# M0A21 register map
File version: 1.0
Registers are 32-bit, read-write, reset 0x0 unless marked. A register's access mark holds for its fields unless they carry their own. Offsets are from the block's base; [hi:lo] are bit positions; {n}, {i} and the like mark numbered series; 'fields as' and 'values as' point back to an identical list.

## SYS — SYS Register Map
Base 0x40000000
0x00 SYS_PDID ro reset not defined — Part Device Identification Number Register
  [31:0] PDID — Part Device Identification Number (Read Only). This register reflects device part number code. Software can read this register to identify which device is used.
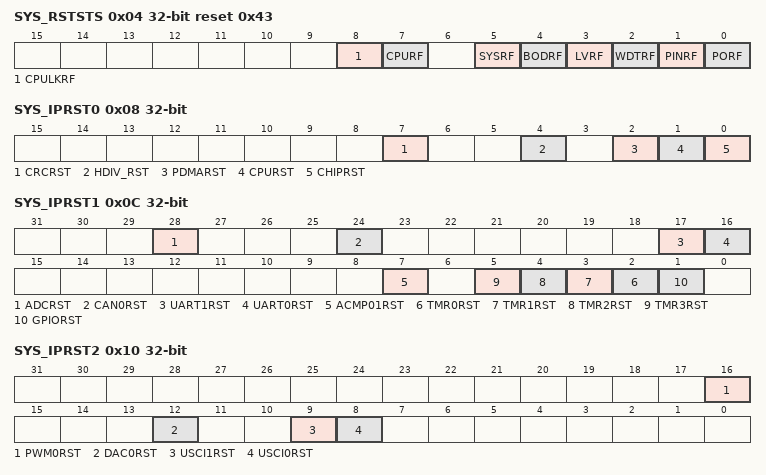
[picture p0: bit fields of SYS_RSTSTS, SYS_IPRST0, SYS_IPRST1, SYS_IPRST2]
0x04 SYS_RSTSTS reset 0x43 — System Reset Status Register
  [8] CPULKRF — CPU Lockup Reset Flag. Note: Write 1 to clear this bit to 0. Note 2: When CPU lockup happened under ICE is connected, This flag will set to 1 but chip will not reset.
    0=No reset from CPU lockup happened; 1=The Cortex-M0 lockup happened and chip is reset
  [7] CPURF — CPU Reset Flag. The CPU reset flag is set by hardware if software writes CPURST (SYS_IPRST0[1]) 1 to reset Cortex- M0 Core and Flash Memory Controller (FMC). Note: Write to clear this bit to 0.
    0=No reset from CPU; 1=The Cortex-M0 Core and FMC are reset by software setting CPURST to 1
  [5] SYSRF — System Reset Flag. The system reset flag is set by the 'Reset Signal' from the Cortex-M0 Core to indicate the previous reset source. Note: Write 1 to clear this bit to 0.
    0=No reset from Cortex-M0; 1=The Cortex- M0 had issued the reset signal to reset the system by writing 1 to the bit SYSRESETREQ(AIRCR[2], Application Interrupt and Reset Control Register, address = 0xE000ED0C) in system control registers of Cortex-M0 core
  [4] BODRF — BOD Reset Flag. The BOD reset flag is set by the 'Reset Signal' from the Brown-Out Detector to indicate the previous reset source. Note: Write 1 to clear this bit to 0.
    0=No reset from BOD; 1=The BOD had issued the reset signal to reset the system
  [3] LVRF — LVR Reset Flag. The LVR reset flag is set by the 'Reset Signal' from the Low Voltage Reset Controller to indicate the previous reset source. Note: Write 1 to clear this bit to 0.
    0=No reset from LVR; 1=LVR controller had issued the reset signal to reset the system
  [2] WDTRF — WDT Reset Flag. The WDT reset flag is set by the 'Reset Signal' from the Watchdog Timer or Window Watchdog Timer to indicate the previous reset source. Note 1: Write 1 to clear this bit to 0. Note 2: Watchdog Timer register RSTF(WDT_CTL[2]) bit is set if the system has been reset by WDT time-out reset. Window Watchdog Timer register WWDTRF(WWDT_STATUS[1]) bit is set if the system has been reset by WWDT time-out reset.
    0=No reset from watchdog timer or window watchdog timer; 1=The watchdog timer or window watchdog timer had issued the reset signal to reset the system
  [1] PINRF — NRESET Pin Reset Flag. The nRESET pin reset flag is set by the 'Reset Signal' from the nRESET Pin to indicate the previous reset source. Note: Write 1 to clear this bit to 0.
    0=No reset from nRESET pin; 1=Pin nRESET had issued the reset signal to reset the system
  [0] PORF — POR Reset Flag. The POR reset flag is set by the 'Reset Signal' from the Power-on Reset (POR) Controller or bit CHIPRST (SYS_IPRST0[0]) to indicate the previous reset source. Note: Write 1 to clear this bit to 0.
    0=No reset from POR or CHIPRST; 1=Power-on Reset (POR) or CHIPRST had issued the reset signal to reset the system
0x08 SYS_IPRST0 — Peripheral Reset Control Register 0
  [7] CRCRST — CRC Calculation Controller Reset (Write Protect). Set this bit to 1 will generate a reset signal to the CRC calculation controller. User needs to set this bit to 0 to release from the reset state. Note: This bit is write protected. Refer to the SYS_REGLCTL register.
    0=CRC calculation controller normal operation; 1=CRC calculation controller reset
  [4] HDIV_RST — HDIV Controller Reset (Write Protect). Set this bit to 1 will generate a reset signal to the hardware divider. User need to set this bit to 0 to release from the reset state. Note: This bit is write protected. Refer to the SYS_REGLCTL register.
    0=Hardware divider controller normal operation; 1=Hardware divider controller reset
  [2] PDMARST — PDMA Controller Reset (Write Protect). Setting this bit to 1 will generate a reset signal to the PDMA. User needs to set this bit to 0 to release from reset state. Note: This bit is write protected. Refer to the SYS_REGLCTL register.
    0=PDMA controller normal operation; 1=PDMA controller reset
  [1] CPURST — Processor Core One-shot Reset (Write Protect). Setting this bit will only reset the processor core and Flash Memory Controller(FMC), and this bit will automatically return to 0 after the 2 clock cycles. Note: This bit is write protected. Refer to the SYS_REGLCTL register.
    0=Processor core normal operation; 1=Processor core one-shot reset
  [0] CHIPRST — Chip One-shot Reset (Write Protect). Setting this bit will reset the whole chip, including Processor core and all peripherals, and this bit will automatically return to 0 after the 2 clock cycles. The CHIPRST is same as the POR reset, all the chip controllers is reset and the chip setting from Flash are also reload. About the difference between CHIPRST and SYSRESETREQ(AIRCR[2]), please refer to section 6.2.2. Note 1: This bit is write protected. Refer to the SYS_REGLCTL register. Note 2: Reset by powr on reset.
    0=Chip normal operation; 1=Chip one-shot reset
0x0C SYS_IPRST1 — Peripheral Reset Control Register 1
  [28] ADCRST — ADC Controller Reset
    0=ADC controller normal operation; 1=ADC controller reset
  [24] CAN0RST — CAN0 Controller Reset
    0=CAN0 controller normal operation; 1=CAN0 controller reset
  [17] UART1RST — UART1 Controller Reset
    0=UART1 controller normal operation; 1=UART1 controller reset
  [16] UART0RST — UART0 Controller Reset
    0=UART0 controller normal operation; 1=UART0 controller reset
  [7] ACMP01RST — Analog Comparator 0/1 Controller Reset
    0=Analog Comparator 0/1 controller normal operation; 1=Analog Comparator 0/1 controller reset
  [n+2] TMR{n}RST (n=0..3) — Timer{n} Controller Reset
    0=Timer{n} controller normal operation; 1=Timer{n} controller reset
  [1] GPIORST — GPIO Controller Reset
    0=GPIO controller normal operation; 1=GPIO controller reset
0x10 SYS_IPRST2 — Peripheral Reset Control Register 2
  [16] PWM0RST — PWM0 Controller Reset
    0=PWM0 controller normal operation; 1=PWM0 controller reset
  [12] DAC0RST — DAC0 Controller Reset
    0=DAC0 controller normal operation; 1=DAC0 controller reset
  [9] USCI1RST — USCI1 Controller Reset
    0=USCI1 controller normal operation; 1=USCI1 controller reset
  [8] USCI0RST — USCI0 Controller Reset
    0=USCI0 controller normal operation; 1=USCI0 controller reset
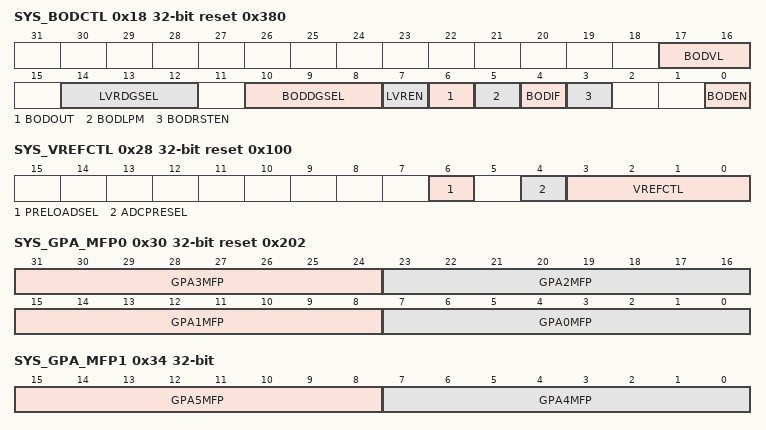
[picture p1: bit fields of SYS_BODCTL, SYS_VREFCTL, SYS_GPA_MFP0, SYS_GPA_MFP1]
0x18 SYS_BODCTL reset 0x380 (reset mask 0xFF00FFF0) — Brown-out Detector Control Register
  [17:16] BODVL — Brown-out Detector Threshold Voltage Selection (Write Protect). The default value is set by Flash controller user configuration register CBOV (CONFIG0 [22:21]). Note: This bit is write protected. Refer to the SYS_REGLCTL register. Note : reset by powr on reset
    0=Brown-Out Detector threshold voltage is 2.3V; 1=Brown-Out Detector threshold voltage is 2.7V; 2=Brown-Out Detector threshold voltage is 3.7V; 3=Brown-Out Detector threshold voltage is 4.4V
  [14:12] LVRDGSEL — LVR Output De-glitch Time Select (Write Protect). Note: These bits are write protected. Refer to the SYS_REGLCTL register.
    0=Without de-glitch function; 1=64 system clock (HCLK); 2=128 system clock (HCLK); 3=256 system clock (HCLK); 4=512 system clock (HCLK); 5=1024 system clock (HCLK); 6=2048 system clock (HCLK); 7=4096 system clock (HCLK)
  [10:8] BODDGSEL — Brown-out Detector Output De-glitch Time Select (Write Protect). Note: These bits are write protected. Refer to the SYS_REGLCTL register.
    0=BOD output is sampled by RC32K clock; 1=64 system clock (HCLK); 2=128 system clock (HCLK); 3=256 system clock (HCLK); 4=512 system clock (HCLK); 5=1024 system clock (HCLK); 6=2048 system clock (HCLK); 7=4096 system clock (HCLK)
  [7] LVREN — Low Voltage Reset Enable Bit (Write Protect). The LVR function resets the chip when the input power voltage is lower than LVR circuit setting. LVR function is enabled by default. Note 1: After enabling the bit, the LVR function will be active with 200us delay for LVR output stable (default). Note 2: This bit is write protected. Refer to the SYS_REGLCTL register.
    0=Low Voltage Reset function Disabled; 1=Low Voltage Reset function Enabled
  [6] BODOUT — Brown-out Detector Output Status. It means the detected voltage is lower than BODVL setting. If the BODEN is 0, BOD function disabled, this bit always responds 0000.
    0=Brown-out Detector output status is 0; 1=Brown-out Detector output status is 1
  [5] BODLPM — Brown-out Detector Low Power Mode (Write Protect). Note 1: The BOD consumes about 100uA in normal mode, the low power mode can reduce the current to about 1/10 but slow the BOD response. Note 2: This bit is write protected. Refer to the SYS_REGLCTL register.
    0=BOD operate in normal mode (default); 1=BOD Low Power mode Enabled
  [4] BODIF — Brown-out Detector Interrupt Flag. Note: Write 1 to clear this bit to 0.
    0=Brown-out Detector does not detect any voltage draft at VDD down through or up through the voltage of BODVL setting; 1=When Brown-out Detector detects the VDD is dropped down through the voltage of BODVL setting or the VDD is raised up through the voltage of BODVL setting, this bit is set to 1 and the brown-out interrupt is requested if brown-out interrupt is enabled
  [3] BODRSTEN — Brown-out Reset Enable Bit (Write Protect). The default value is set by Flash controller user configuration register CBORST(CONFIG0[20]) bit . Note 1: While the Brown-out Detector function is enabled (BODEN high) and BOD reset function is enabled (BODRSTEN high), BOD will assert a signal to reset chip when the detected voltage is lower than the threshold (BODOUT high). While the BOD function is enabled (BODEN high) and BOD interrupt function is enabled (BODRSTEN low), BOD will assert an interrupt if BODOUT is high. BOD interrupt will keep till to the BODEN set to 0. BOD interrupt can be blocked by disabling the NVIC BOD interrupt or disabling BOD function (set BODEN low). Note 2: This bit is write protected. Refer to the SYS_REGLCTL register. Note 3: Reset by powr on reset.
    0=Brown-out 'INTERRUPT' function Enabled; 1=Brown-out 'RESET' function Enabled
  [0] BODEN — Brown-out Detector Enable Bit (Write Protect). The default value is set by Flash controller user configuration register CBODEN (CONFIG0 [19]). Note 1: This bit is write protected. Refer to the SYS_REGLCTL register. Note 2: Reset by powr on reset.
    0=Brown-out Detector function Disabled; 1=Brown-out Detector function Enabled
0x1C SYS_IVSCTL — Internal Voltage Source Control Register
  [0] VTEMPEN — Temperature Sensor Enable Bit. This bit is used to enable/disable temperature sensor function. Note: After this bit is set to 1, the value of temperature sensor output can be obtained from ADC conversion result. Please refer to ADC function chapter for details.
    0=Temperature sensor function Disabled (default); 1=Temperature sensor function Enabled
0x24 SYS_PORCTL — Power-On-reset Controller Register
  [15:0] POROFF — Power-on Reset Enable Bit (Write Protect). When powered on, the POR circuit generates a reset signal to reset the whole chip function, but noise on the power may cause the POR active again. User can disable internal POR circuit to avoid unpredictable noise to cause chip reset by writing 0x5AA5 to this field. The POR function will be active again when this field is set to another value or chip is reset by other reset source, including: nRESET, Watchdog, LVR reset, BOD reset, ICE reset command and the software-chip reset function. Note: This bit is write protected. Refer to the SYS_REGLCTL register.
0x28 SYS_VREFCTL reset 0x100 — VREF Control Register
  [6] PRELOADSEL — Pre-load Timing Selection (Write Protect). Note: These bits is write protected. Refer to the SYS_REGLCTL register.
    0=Pre-load time is 60us for 0.1uF Capacitor; 1=Pre-load time is 310us for 1uF Capacitor
  [4] ADCPRESEL — ADC Voltage Reference. Note: These bits is write protected. Refer to the SYS_REGLCTL register.
    0=ADC positive reference voltage comes from AVDD (voltage of VDD pin); 1=ADC positive reference voltage comes from internal or external VREF
  [3:0] VREFCTL — VREF Control Bits (Write Protect). Note 1: GPA1 needs to keep folating if Internal voltage reference is enabled. Note 2: These bits are write protected. Refer to the SYS_REGLCTL register.
    0=VREF is from external pin; 1=VREF is internal 1.536V; 3=VREF is internal 2.048V; 5=VREF is internal 2.56V; 7=VREF is internal 3.072V; 9=VREF is internal 4.096V
0x30 SYS_GPA_MFP0 reset 0x202 — GPIOA Multiple Function Control Register 0
  [31:24] GPA3MFP — PA.3 Multi-function Pin Selection
  [23:16] GPA2MFP — PA.2 Multi-function Pin Selection
  [15:8] GPA1MFP — PA.1 Multi-function Pin Selection
  [7:0] GPA0MFP — PA.0 Multi-function Pin Selection
0x34 SYS_GPA_MFP1 — GPIOA Multiple Function Control Register 1
  [15:8] GPA5MFP — PA.5 Multi-function Pin Selection
  [7:0] GPA4MFP — PA.4 Multi-function Pin Selection
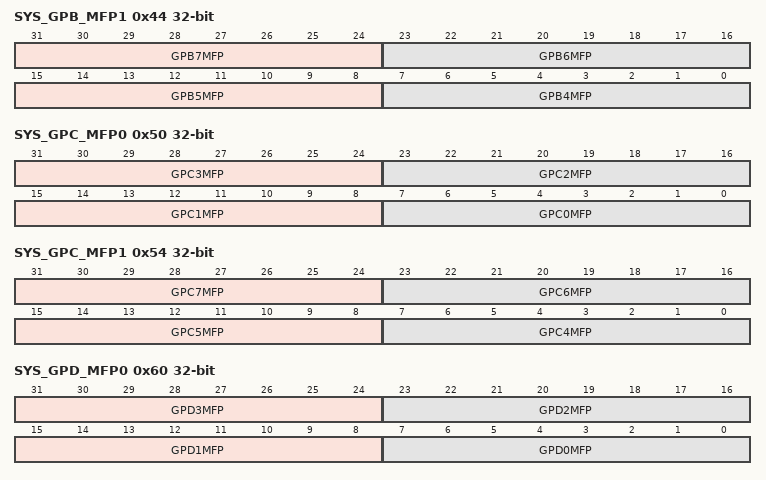
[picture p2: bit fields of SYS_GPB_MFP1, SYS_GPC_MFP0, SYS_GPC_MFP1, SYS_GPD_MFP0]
0x44 SYS_GPB_MFP1 — GPIOB Multiple Function Control Register 1
  [31:24] GPB7MFP — PB.7 Multi-function Pin Selection
  [23:16] GPB6MFP — PB.6 Multi-function Pin Selection
  [15:8] GPB5MFP — PB.5 Multi-function Pin Selection
  [7:0] GPB4MFP — PB.4 Multi-function Pin Selection
0x50 SYS_GPC_MFP0 — GPIOC Multiple Function Control Register 0
  [31:24] GPC3MFP — PC3 Multi-function Pin Selection
  [23:16] GPC2MFP — PC.2 Multi-function Pin Selection
  [15:8] GPC1MFP — PC.1 Multi-function Pin Selection
  [7:0] GPC0MFP — PC.0 Multi-function Pin Selection
0x54 SYS_GPC_MFP1 — GPIOC Multiple Function Control Register 1
  [31:24] GPC7MFP — PC.7Multi-function Pin Selection
  [23:16] GPC6MFP — PC.6 Multi-function Pin Selection
  [15:8] GPC5MFP — PC.5 Multi-function Pin Selection
  [7:0] GPC4MFP — PC.4 Multi-function Pin Selection
0x60 SYS_GPD_MFP0 — GPIOD Multiple Function Control Register 0
  [31:24] GPD3MFP — PD3 Multi-function Pin Selection
  [23:16] GPD2MFP — PD.2 Multi-function Pin Selection
  [15:8] GPD1MFP — PD.1 Multi-function Pin Selection
  [7:0] GPD0MFP — PD.0 Multi-function Pin Selection
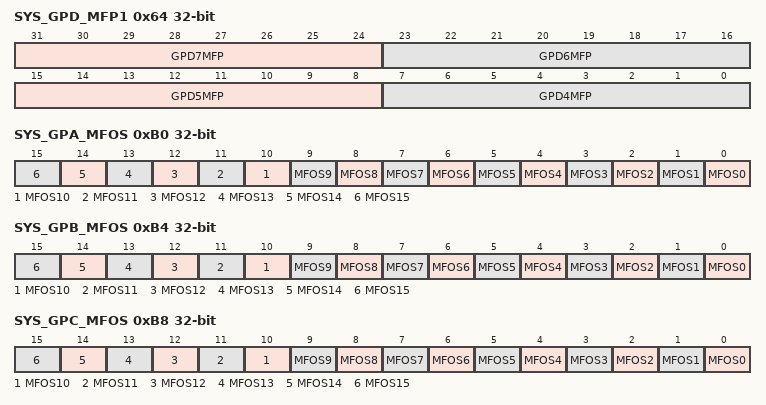
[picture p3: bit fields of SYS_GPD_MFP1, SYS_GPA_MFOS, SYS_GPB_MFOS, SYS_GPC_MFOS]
0x64 SYS_GPD_MFP1 — GPIOD Multiple Function Control Register 1
  [31:24] GPD7MFP — PD.7Multi-function Pin Selection
  [23:16] GPD6MFP — PD.6 Multi-function Pin Selection
  [15:8] GPD5MFP — PD.5 Multi-function Pin Selection
  [7:0] GPD4MFP — PD.4 Multi-function Pin Selection
0xB0 SYS_GPA_MFOS — GPIOA Multiple Function Output Select Register
  [all] fields
    0=Multiple funtion pin output mode type is unchanged; 1=Multiple funtion pin output mode type is Open-drain mode
  [n] MFOS{n} (n=0..15) — GPIOA-h Pin[n] Multiple Function Pin Output Mode Select. This bit used to select multiple function pin output mode type for Px.n pin. If MFOS is enabled then GPIO mode setting is ignored when MFP setting be GPIO.
0xB4 SYS_GPB_MFOS — GPIOB Multiple Function Output Select Register
  fields as SYS_GPA_MFOS
0xB8 SYS_GPC_MFOS — GPIOC Multiple Function Output Select Register
  fields as SYS_GPA_MFOS
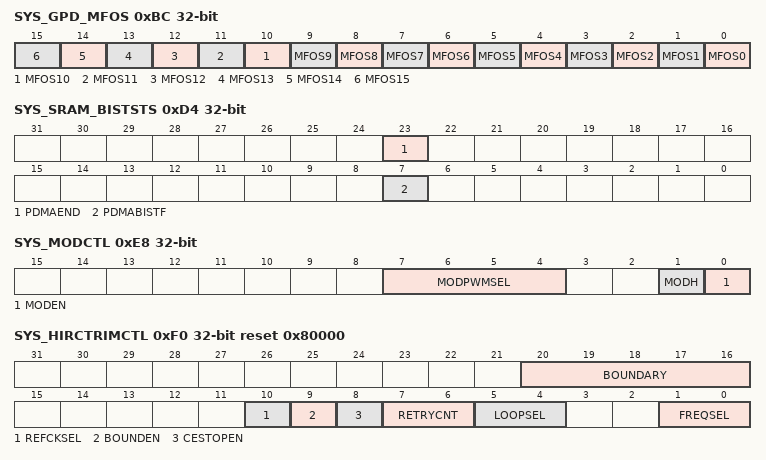
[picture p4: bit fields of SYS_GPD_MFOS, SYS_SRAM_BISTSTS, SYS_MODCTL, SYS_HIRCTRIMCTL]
0xBC SYS_GPD_MFOS — GPIOD Multiple Function Output Select Register
  fields as SYS_GPA_MFOS
0xD0 SYS_SRAM_BISTCTL — System SRAM BIST Test Control Register
  [7] PDMABIST — PDMA BIST Enable Bit (Write Protect). This bit enables BIST test for PDMA RAM. Note: This bit is write protected. Refer to the SYS_REGLCTL register.
    0=system PDMA BIST Disabled; 1=system PDMA BIST Enabled
0xD4 SYS_SRAM_BISTSTS ro (reset mask 0xFF00FF00) — System SRAM BIST Test Status Register
  [23] PDMAEND — PDMA SRAM BIST Test Finish
    0=PDMA SRAM BIST is active; 1=PDMA SRAM BIST test finished
  [7] PDMABISTF — PDMA SRAM BIST Failed Flag
    0=PDMA SRAM BIST pass; 1=PDMA SRAM BIST failed
0xE8 SYS_MODCTL — Modulation Control Register
  [7:4] MODPWMSEL — PWM0 Channel Select for Modulation. Select the PWM0 channel to modulate with the UART0_TXD or USCI0_DAT0. 0000: PWM0 Channel 0 modulate with UART0_TXD. 0001: PWM0 Channel 1 modulate with UART0_TXD. 0010: PWM0 Channel 2 modulate with UART0_TXD. 0011: PWM0 Channel 3 modulete with UART0_TXD. 0100: PWM0 Channel 4 modulete with UART0_TXD. 0101: PWM0 Channel 5 modulete with UART0_TXD. 0110: Reserved. 0111: Reserved. 1000: PWM0 Channel 0 modulate with USCI0_DAT0. 1001: PWM0 Channel 1 modulate with USCI0_DAT0. 1010: PWM0 Channel 2 modulate with USCI0_DAT0. 1011: PWM0 Channel 3 modulete with USCI0_DAT0. 1100: PWM0 Channel 4 modulete with USCI0_DAT0. 1101: PWM0 Channel 5 modulete with USCI0_DAT0. 1110: Reserved. 1111: Reserved. Note: This bis is valid while MODEN (SYS_MODCTL[0]) is set to 1.
  [1] MODH — Modulation at Data High. Select modulation pulse(PWM0) at high or low of UART0_TXD or USCI0_DAT0
    0=Modulation pulse at UART0_TXD low or USCI0_DAT0 low; 1=Modulation pulse at UART0_TXD high or USCI0_DAT0 high
  [0] MODEN — Modulation Function Enable Bit. This bit enables modulation funcion by modulating with PWM0 channel output and USCI0(USCI0_DAT0) or UART0(UART0_TXD) output.
    0=Modulation Function Disabled; 1=Modulation Function Enabled
0xF0 SYS_HIRCTRIMCTL reset 0x80000 — HIRC Trim Control Register
  [20:16] BOUNDARY — Boundary Selection. Fill the boundary range from 0x1 to 0x1F, 0x0 is reserved. Note: This field is effective only when the BOUNDEN(SYS_HIRCTRIMCTL[9]) is enable.
  [10] REFCKSEL — Reference Clock Selection. Note: If there is no reference clock (LXT) when the rc_trim is enabled, CLKERIF (SYS_HIRCTRIMCTL[2]) will be set to 1.
    0=HIRC trim reference clock is from LXT (32.768 kHz)
  [9] BOUNDEN — Boundary Enable Bit
    0=Boundary function Disabled; 1=Boundary function Enabled
  [8] CESTOPEN — Clock Error Stop Enable Bit
    0=The trim operation is keep going if clock is inaccuracy; 1=The trim operation is stopped if clock is inaccuracy
  [7:6] RETRYCNT — Trim Value Update Limitation Count. This field defines that how many times the auto trim circuit will try to update the HIRC trim value before the frequency of HIRC locked. Once the HIRC locked, the internal trim value update counter will be reset. If the trim value update counter reached this limitation value and frequency of HIRC still doesn't lock, the auto trim operation will be disabled and FREQSEL will be cleared to 00.
    0=Trim retry count limitation is 64 loops; 1=Trim retry count limitation is 128 loops; 2=Trim retry count limitation is 256 loops; 3=Trim retry count limitation is 512 loops
  [5:4] LOOPSEL — Trim Calculation Loop Selection. This field defines that trim value calculation is based on how many reference clocks. Note: For example, if LOOPSEL is set as 00, auto trim circuit will calculate trim value based on the average frequency difference in 4 clocks of reference clock.
    0=Trim value calculation is based on average difference in 4 clocks of reference clock; 1=Trim value calculation is based on average difference in 8 clocks of reference clock; 2=Trim value calculation is based on average difference in 16 clocks of reference clock; 3=Trim value calculation is based on average difference in 32 clocks of reference clock
  [1:0] FREQSEL — Trim Frequency Selection. This field indicates the target frequency of 48 MHz internal high speed RC oscillator (HIRC) auto trim. During auto trim operation, if clock error detected with CESTOPEN is set to 1 or trim retry limitation count reached, this field will be cleared to 00 automatically.
    0=Disable HIRC auto trim function; 1=Enable HIRC auto trim function and trim HIRC to 48 MHz
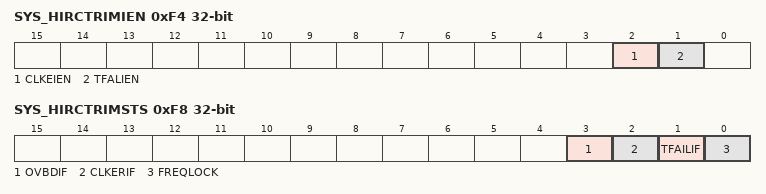
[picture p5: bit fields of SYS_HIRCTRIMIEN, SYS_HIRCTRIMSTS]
0xF4 SYS_HIRCTRIMIEN — HIRC Trim Interrupt Enable Register
  [2] CLKEIEN — Clock Error Interrupt Enable Bit. This bit controls if CPU would get an interrupt while clock is inaccuracy during auto trim operation. If this bit is set to1, and CLKERRIF(SYS_HIRCTRIMSTS[2]) is set during auto trim operation, an interrupt will be triggered to notify the clock frequency is inaccuracy.
    0=Disable CLKERRIF(SYS_HIRCTRIMSTS[2]) status to trigger an interrupt to CPU; 1=Enable CLKERRIF(SYS_HIRCTRIMSTS[2]) status to trigger an interrupt to CPU
  [1] TFALIEN — Trim Failure Interrupt Enable Bit. This bit controls if an interrupt will be triggered while HIRC trim value update limitation count reached and HIRC frequency still not locked on target frequency set by FREQSEL(SYS_HIRCTRIMCTL[1:0]). If this bit is high and TFAILIF(SYS_HIRCTRIMSTS[1]) is set during auto trim operation, an interrupt will be triggered to notify that HIRC trim value update limitation count was reached.
    0=Disable TFAILIF(SYS_HIRCTRIMSTS[1]) status to trigger an interrupt to CPU; 1=Enable TFAILIF(SYS_HIRCTRIMSTS[1]) status to trigger an interrupt to CPU
0xF8 SYS_HIRCTRIMSTS — HIRC Trim Interrupt Status Register
  [3] OVBDIF — Over Boundary Status. When the over boundary function is set, if there occurs the over boundary condition, this flag will be set. Note: Write 1 to clear this flag.
    0=Over boundary coundition did not occur; 1=Over boundary coundition occurred
  [2] CLKERIF — Clock Error Interrupt Status. When the frequency relation between reference clock and 48 MHz internal high speed RC oscillator (HIRC) is shift larger to unreasonable value, this bit will be set and to be an indicate that clock frequency is inaccuracy. Once this bit is set to 1, the auto trim operation stopped and FREQSEL(SYS_HIRCTRIMCTL[1:0]) will be cleared to 00 by hardware automatically if CESTOPEN(SYS_HIRCTRIMCTL[8]) is set to 1. If this bit is set and CLKEIEN(SYS_HIRCTIEN[2]) is high, an interrupt will be triggered to notify the clock frequency is inaccuracy. Write 1 to clear this to 0. Note : reset by powr on reset
    0=Clock frequency is accuracy; 1=Clock frequency is inaccuracy
  [1] TFAILIF — Trim Failure Interrupt Status. This bit indicates that HIRC trim value update limitation count reached and the HIRC clock frequency still doesn't be locked. Once this bit is set, the auto trim operation stopped and FREQSEL(SYS_HIRCTRIMCTL[1:0]) will be cleared to 00 by hardware automatically. If this bit is set and TFAILIEN(SYS_HIRCIEN[1]) is high, an interrupt will be triggered to notify that HIRC trim value update limitation count was reached. Write 1 to clear this to 0. Note : reset by powr on reset
    0=Trim value update limitation count does not reach; 1=Trim value update limitation count reached and HIRC frequency still not locked
  [0] FREQLOCK — HIRC Frequency Lock Status. This bit indicates the HIRC frequency is locked. This is a status bit and doesn't trigger any interrupt. Write 1 to clear this to 0. This bit will be set automatically, if the frequecy is lock and the RC_TRIM is enabled. Note : Reset by powr on reset.
    0=The internal high-speed oscillator frequency doesn't lock at 48 MHz yet; 1=The internal high-speed oscillator frequency locked at 48 MHz
0x100 SYS_REGLCTL — Register Lock Control Register
  [7:0] REGLCTL wo — Register Lock Control Code (Write Only). Some registers have write-protection function. Writing these registers have to disable the protected function by writing the sequence value '59h', '16h', '88h' to this field. After this sequence is completed, the REGLCTL bit will be set to 1 and write-protection registers can be normal write. REGLCTL[0]. Register Lock Control Disable Index (Read Only)
    0=Write-protection Enabled for writing protected registers. Any write to the protected register is ignored; 1=Write-protection Disabled for writing protected registers
0x1EC SYS_PORDISAN — Analog POR Disable Control Register
  [15:0] POROFFAN — Power-on Reset Enable Bit (Write Protect). After powered on, User can turn off internal analog POR circuit to save power by writing 0x5AA5 to this field. The analog POR circuit will be active again when this field is set to another value or chip is reset by other reset source, including: nRESET, Watchdog, LVR reset, BOD reset, ICE reset command and the software-chip reset function. Note: This bit is write protected. Refer to the SYS_REGLCTL register.
